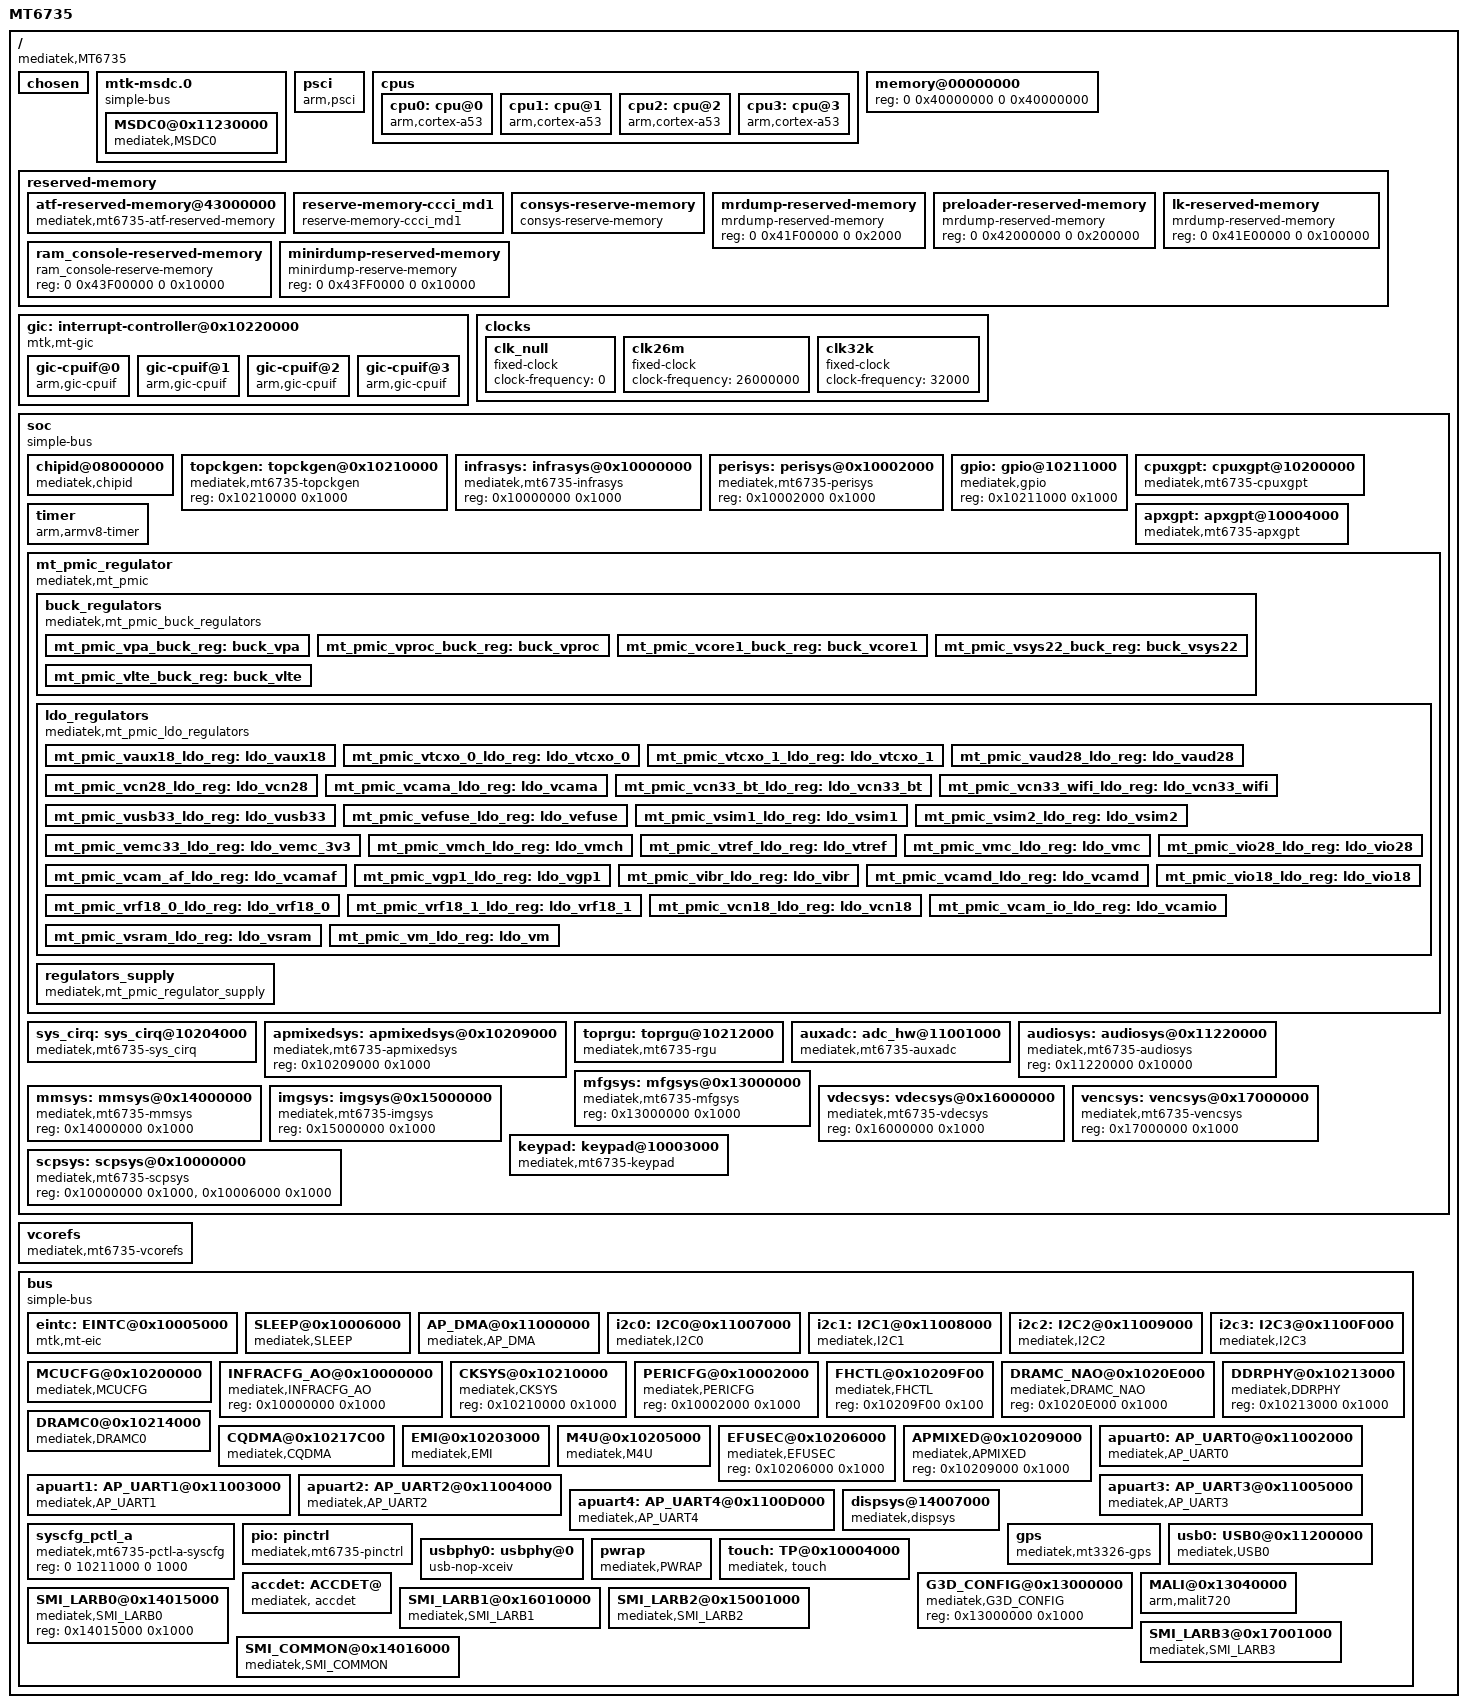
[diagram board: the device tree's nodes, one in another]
/*
 * Mediatek's MT6735 SoC device tree source
 *
 * Copyright (c) 2013 MediaTek Co., Ltd.
 *              http://www.mediatek.com
 *
 */

#include <dt-bindings/clock/mt6735-clk.h>
#include <dt-bindings/interrupt-controller/arm-gic.h>
#include <dt-bindings/interrupt-controller/irq.h>
#include "mt6735-pinfunc.h"

/ {
	model = "MT6735";
	compatible = "mediatek,MT6735";
	interrupt-parent = <&gic>;
	#address-cells = <2>;
	#size-cells = <2>;

	/* chosen */
	chosen {
		bootargs = "console=tty0 console=ttyMT0,921600n1 root=/dev/ram \
initrd=0x44000000,0x300000 loglevel=8 androidboot.hardware=mt6735";
	};

	/* Do not put any bus before mtk-msdc, because it should be mtk-msdc.0 for partition device node usage */
	/*workaround for .0*/
	mtk-msdc.0 {
		compatible = "simple-bus";
		#address-cells = <1>;
		#size-cells = <1>;
		ranges = <0 0 0 0xffffffff>;

		MSDC0@0x11230000 {
			compatible = "mediatek,MSDC0";
			reg = <0x11230000 0x10000  /* MSDC0_BASE   */
			       0x10000E84 0x2>;    /* FPGA PWR_GPIO, PWR_GPIO_EO */
			interrupts = <0 79 0x8>;
		};
	};

	psci {
		compatible  = "arm,psci";
		method      = "smc";
		cpu_suspend = <0x84000001>;
		cpu_off     = <0x84000002>;
		cpu_on      = <0x84000003>;
		affinity_info = <0x84000004>;
	};

	cpus {	#address-cells = <1>;
		#size-cells = <0>;

		cpu0: cpu@0 {
			device_type = "cpu";
			compatible = "arm,cortex-a53";
			reg = <0x000>;
			enable-method = "mt-boot";
			cpu-release-addr = <0x0 0x40000200>;
			clock-frequency = <1300000000>;
		};

		cpu1: cpu@1 {
			device_type = "cpu";
			compatible = "arm,cortex-a53";
			reg = <0x001>;
			enable-method = "mt-boot";
			cpu-release-addr = <0x0 0x40000200>;
			clock-frequency = <1300000000>;
		};

		cpu2: cpu@2 {
			device_type = "cpu";
			compatible = "arm,cortex-a53";
			reg = <0x002>;
			enable-method = "mt-boot";
			cpu-release-addr = <0x0 0x40000200>;
			clock-frequency = <1300000000>;
		};

		cpu3: cpu@3 {
			device_type = "cpu";
			compatible = "arm,cortex-a53";
			reg = <0x003>;
			enable-method = "mt-boot";
			cpu-release-addr = <0x0 0x40000200>;
			clock-frequency = <1300000000>;
		};
/*
		cpu4: cpu@4 {
			device_type = "cpu";
			compatible = "arm,cortex-a53";
			reg = <0x100>;
			enable-method = "mt-boot";
			cpu-release-addr = <0x0 0x40000200>;
			clock-frequency = <2000000000>;
		};

		cpu5: cpu@5 {
			device_type = "cpu";
			compatible = "arm,cortex-a53";
			reg = <0x101>;
			enable-method = "mt-boot";
			cpu-release-addr = <0x0 0x40000200>;
			clock-frequency = <2000000000>;
		};

		cpu6: cpu@6 {
			device_type = "cpu";
			compatible = "arm,cortex-a53";
			reg = <0x102>;
			enable-method = "mt-boot";
			cpu-release-addr = <0x0 0x40000200>;
			clock-frequency = <2000000000>;
		};

		cpu7: cpu@7 {
			device_type = "cpu";
			compatible = "arm,cortex-a53";
			reg = <0x103>;
			enable-method = "mt-boot";
			cpu-release-addr = <0x0 0x40000200>;
			clock-frequency = <2000000000>;

		};
*/
	};

	memory@00000000 {
		device_type = "memory";
		reg = <0 0x40000000 0 0x40000000>;
	};

	reserved-memory {
		#address-cells = <2>;
		#size-cells = <2>;
		ranges;

		/* reserve 192KB at DRAM start + 48MB */
		atf-reserved-memory@43000000 {
			compatible = "mediatek,mt6735-atf-reserved-memory",
				     "mediatek,mt6735m-atf-reserved-memory",
				     "mediatek,mt6753-atf-reserved-memory";
			no-map;
			reg = <0 0x43000000 0 0x30000>;
		};

		reserve-memory-ccci_md1 {
			compatible = "reserve-memory-ccci_md1";
			no-map;
			size = <0 0x3810000>; // md_size+smem_size
			alignment = <0 0x2000000>;
			alloc-ranges = <0 0x40000000 0 0xC0000000>;
		};

		consys-reserve-memory {
			compatible = "consys-reserve-memory";
			no-map;
			size = <0 0x200000>;
			alignment = <0 0x200000>;
		};

		mrdump-reserved-memory {
			compatible = "mrdump-reserved-memory";
			reg = <0 0x41F00000 0 0x2000>;
		};

		preloader-reserved-memory {
			compatible = "mrdump-reserved-memory";
			reg = <0 0x42000000 0 0x200000>;
		};

		lk-reserved-memory {
			compatible = "mrdump-reserved-memory";
			reg = <0 0x41E00000 0 0x100000>;
		};


		/*
		reserve-memory-test {
			compatible = "reserve-memory-test";
			no-map;
			size = <0 0x4000000>;
			alignment = <0 0x2000000>;
		};

		mrdump-reserved-memory {
			compatible = "mrdump";
			reg = <0 0x80000000 0 0x4000000>;
		};
		*/
		ram_console-reserved-memory {
			compatible = "ram_console-reserve-memory";
			reg = <0 0x43F00000 0 0x10000>;
		};

		minirdump-reserved-memory {
			compatible = "minirdump-reserve-memory";
			reg = <0 0x43FF0000 0 0x10000>;
		};
	};

	gic: interrupt-controller@0x10220000 {
		compatible = "mtk,mt-gic";
		#interrupt-cells = <3>;
		#address-cells = <0>;
		interrupt-controller;
		reg = <0 0x10221000 0 0x1000>,
			<0 0x10222000 0 0x1000>,
			<0 0x10200620 0 0x1000>;
		interrupts = <1 9 0xf04>;

		gic-cpuif@0 {
			compatible = "arm,gic-cpuif";
			cpuif-id = <0>;
			cpu = <&cpu0>;
		};

		gic-cpuif@1 {
			compatible = "arm,gic-cpuif";
			cpuif-id = <1>;
			cpu = <&cpu1>;
		};

		gic-cpuif@2 {
			compatible = "arm,gic-cpuif";
			cpuif-id = <2>;
			cpu = <&cpu2>;
		};

		gic-cpuif@3 {
			compatible = "arm,gic-cpuif";
			cpuif-id = <3>;
			cpu = <&cpu3>;
		};


	};

	clocks {
		clk_null: clk_null {
			compatible = "fixed-clock";
			#clock-cells = <0>;
			clock-frequency = <0>;
		};

		clk26m: clk26m {
			compatible = "fixed-clock";
			#clock-cells = <0>;
			clock-frequency = <26000000>;
		};

		clk32k: clk32k {
			compatible = "fixed-clock";
			#clock-cells = <0>;
			clock-frequency = <32000>;
		};
	};

	soc {
		compatible = "simple-bus";
		#address-cells = <1>;
		#size-cells = <1>;
		ranges;

		chipid@08000000 {
			compatible = "mediatek,chipid";
			reg = <0x08000000 0x0004>,
					<0x08000004 0x0004>,
					<0x08000008 0x0004>,
					<0x0800000C 0x0004>;
		};

		topckgen: topckgen@0x10210000 {
			compatible = "mediatek,mt6735-topckgen";
			reg = <0x10210000 0x1000>;
			#clock-cells = <1>;
		};

		infrasys: infrasys@0x10000000 {
			compatible = "mediatek,mt6735-infrasys";
			reg = <0x10000000 0x1000>;
			#clock-cells = <1>;
		};

		perisys: perisys@0x10002000 {
			compatible = "mediatek,mt6735-perisys";
			reg = <0x10002000 0x1000>;
			#clock-cells = <1>;
		};

		gpio: gpio@10211000 {
			compatible = "mediatek,gpio";
			reg = <0x10211000 0x1000>;
		};

		cpuxgpt: cpuxgpt@10200000 {
			compatible = "mediatek,mt6735-cpuxgpt";
			reg = <0x10200000 0x1000>;
			interrupts = <GIC_SPI 64 IRQ_TYPE_LEVEL_HIGH>,
				<GIC_SPI 65 IRQ_TYPE_LEVEL_HIGH>,
				<GIC_SPI 66 IRQ_TYPE_LEVEL_HIGH>,
				<GIC_SPI 67 IRQ_TYPE_LEVEL_HIGH>,
				<GIC_SPI 68 IRQ_TYPE_LEVEL_HIGH>,
				<GIC_SPI 69 IRQ_TYPE_LEVEL_HIGH>,
				<GIC_SPI 70 IRQ_TYPE_LEVEL_HIGH>,
				<GIC_SPI 71 IRQ_TYPE_LEVEL_HIGH>;
		};

		apxgpt: apxgpt@10004000 {
			compatible = "mediatek,mt6735-apxgpt";
			reg = <0x10004000 0x1000>;
			interrupts = <GIC_SPI 152 IRQ_TYPE_LEVEL_LOW>;
			clock-frequency = <13000000>;
		};

		timer {
			compatible = "arm,armv8-timer";
			interrupts = <GIC_PPI 13 IRQ_TYPE_LEVEL_LOW>, /*Secure Physical Timer Event*/
				<GIC_PPI 14 IRQ_TYPE_LEVEL_LOW>, /*Non-Secure Physical Timer Event*/
				<GIC_PPI 11 IRQ_TYPE_LEVEL_LOW>, /*Virtual Timer Event*/
				<GIC_PPI 10 IRQ_TYPE_LEVEL_LOW>; /*Hypervisor Timer Event*/
				clock-frequency = <13000000>;
		};

		mt_pmic_regulator {
			compatible = "mediatek,mt_pmic";
			/*reg = <0x01>*/
			buck_regulators {
			compatible = "mediatek,mt_pmic_buck_regulators";
				mt_pmic_vpa_buck_reg: buck_vpa {
					regulator-name = "vpa";
					regulator-min-microvolt = <500000>;
					regulator-max-microvolt = <3650000>;
					regulator-ramp-delay = <50000>;
					regulator-enable-ramp-delay = <180>;
				};
				mt_pmic_vproc_buck_reg: buck_vproc {
					regulator-name = "vproc";
					regulator-min-microvolt = <600000>;
					regulator-max-microvolt = <1393750>;
					regulator-ramp-delay = <6250>;
					regulator-enable-ramp-delay = <180>;
					regulator-always-on;
					regulator-boot-on;
				};
				mt_pmic_vcore1_buck_reg: buck_vcore1 {
					regulator-name = "vcore1";
					regulator-min-microvolt = <600000>;
					regulator-max-microvolt = <1393750>;
					regulator-ramp-delay = <6250>;
					regulator-enable-ramp-delay = <180>;
					regulator-always-on;
					regulator-boot-on;
				};
				mt_pmic_vsys22_buck_reg: buck_vsys22 {
					regulator-name = "vsys22";
					regulator-min-microvolt = <1200000>;
					regulator-max-microvolt = <1993750>;
					regulator-ramp-delay = <6250>;
					regulator-enable-ramp-delay = <180>;
					regulator-always-on;
					regulator-boot-on;
				};
				mt_pmic_vlte_buck_reg: buck_vlte {
					regulator-name = "vlte";
					regulator-min-microvolt = <600000>;
					regulator-max-microvolt = <1393750>;
					regulator-ramp-delay = <6250>;
					regulator-enable-ramp-delay = <180>;
					regulator-always-on;
					regulator-boot-on;
				};
			};	/* End of buck_regulators */
			ldo_regulators {
				compatible = "mediatek,mt_pmic_ldo_regulators";
				mt_pmic_vaux18_ldo_reg: ldo_vaux18 {
					regulator-name = "vaux18";
					regulator-min-microvolt = <1800000>;
					regulator-max-microvolt = <1800000>;
					regulator-enable-ramp-delay = <264>;
					regulator-boot-on;
				};
				mt_pmic_vtcxo_0_ldo_reg: ldo_vtcxo_0 {
					regulator-name = "vtcxo_0";
					regulator-min-microvolt = <2800000>;
					regulator-max-microvolt = <2800000>;
					regulator-enable-ramp-delay = <110>;
					regulator-boot-on;
				};
				mt_pmic_vtcxo_1_ldo_reg: ldo_vtcxo_1 {
					regulator-name = "vtcxo_1";
					regulator-min-microvolt = <2800000>;
					regulator-max-microvolt = <2800000>;
					regulator-enable-ramp-delay = <110>;
				};
				mt_pmic_vaud28_ldo_reg: ldo_vaud28 {
					regulator-name = "vaud28";
					regulator-min-microvolt = <2800000>;
					regulator-max-microvolt = <2800000>;
					regulator-enable-ramp-delay = <264>;
					regulator-boot-on;
				};
				mt_pmic_vcn28_ldo_reg: ldo_vcn28 {
					regulator-name = "vcn28";
					regulator-min-microvolt = <2800000>;
					regulator-max-microvolt = <2800000>;
					regulator-enable-ramp-delay = <264>;
				};
				mt_pmic_vcama_ldo_reg: ldo_vcama {
					regulator-name = "vcama";
					regulator-min-microvolt = <1500000>;
					regulator-max-microvolt = <2800000>;
					regulator-enable-ramp-delay = <264>;
				};
				mt_pmic_vcn33_bt_ldo_reg: ldo_vcn33_bt {
					regulator-name = "vcn33_bt";
					regulator-min-microvolt = <3300000>;
					regulator-max-microvolt = <3600000>;
					regulator-enable-ramp-delay = <264>;
				};
				mt_pmic_vcn33_wifi_ldo_reg: ldo_vcn33_wifi {
					regulator-name = "vcn33_wifi";
					regulator-min-microvolt = <3300000>;
					regulator-max-microvolt = <3600000>;
					regulator-enable-ramp-delay = <264>;
				};
				mt_pmic_vusb33_ldo_reg: ldo_vusb33 {
					regulator-name = "vusb33";
					regulator-min-microvolt = <3300000>;
					regulator-max-microvolt = <3300000>;
					regulator-enable-ramp-delay = <264>;
					regulator-boot-on;
				};
				mt_pmic_vefuse_ldo_reg: ldo_vefuse {
					regulator-name = "vefuse";
					regulator-min-microvolt = <1800000>;
					regulator-max-microvolt = <2200000>;
					regulator-enable-ramp-delay = <264>;
				};
				mt_pmic_vsim1_ldo_reg: ldo_vsim1 {
					regulator-name = "vsim1";
					regulator-min-microvolt = <1700000>;
					regulator-max-microvolt = <2100000>;
					regulator-enable-ramp-delay = <264>;
				};
				mt_pmic_vsim2_ldo_reg: ldo_vsim2 {
					regulator-name = "vsim2";
					regulator-min-microvolt = <1700000>;
					regulator-max-microvolt = <2100000>;
					regulator-enable-ramp-delay = <264>;
				};
				mt_pmic_vemc33_ldo_reg: ldo_vemc_3v3 {
					regulator-name = "vemc_3v3";
					regulator-min-microvolt = <1800000>;
					regulator-max-microvolt = <3300000>;
					regulator-enable-ramp-delay = <264>;
					regulator-boot-on;
				};
				mt_pmic_vmch_ldo_reg: ldo_vmch {
					regulator-name = "vmch";
					regulator-min-microvolt = <2900000>;
					regulator-max-microvolt = <3300000>;
					regulator-enable-ramp-delay = <44>;
					regulator-boot-on;
				};
				mt_pmic_vtref_ldo_reg: ldo_vtref {
					regulator-name = "vtref";
					regulator-min-microvolt = <1800000>;
					regulator-max-microvolt = <1800000>;
					regulator-enable-ramp-delay = <240>;
				};
				mt_pmic_vmc_ldo_reg: ldo_vmc {
					regulator-name = "vmc";
					regulator-min-microvolt = <1800000>;
					regulator-max-microvolt = <3300000>;
					regulator-enable-ramp-delay = <44>;
					regulator-boot-on;
				};
				mt_pmic_vcam_af_ldo_reg: ldo_vcamaf {
					regulator-name = "vcamaf";
					regulator-min-microvolt = <1200000>;
					regulator-max-microvolt = <3300000>;
					regulator-enable-ramp-delay = <264>;
				};
				mt_pmic_vio28_ldo_reg: ldo_vio28 {
					regulator-name = "vio28";
					regulator-min-microvolt = <2800000>;
					regulator-max-microvolt = <2800000>;
					regulator-enable-ramp-delay = <264>;
					regulator-boot-on;
				};
				mt_pmic_vgp1_ldo_reg: ldo_vgp1 {
					regulator-name = "vgp1";
					regulator-min-microvolt = <1200000>;
					regulator-max-microvolt = <3300000>;
					regulator-enable-ramp-delay = <264>;
				};
				mt_pmic_vibr_ldo_reg: ldo_vibr {
					regulator-name = "vibr";
					regulator-min-microvolt = <1200000>;
					regulator-max-microvolt = <3300000>;
					regulator-enable-ramp-delay = <44>;
				};
				mt_pmic_vcamd_ldo_reg: ldo_vcamd {
					regulator-name = "vcamd";
					regulator-min-microvolt = <900000>;
					regulator-max-microvolt = <1500000>;
					regulator-enable-ramp-delay = <264>;
				};
				mt_pmic_vrf18_0_ldo_reg: ldo_vrf18_0 {
					regulator-name = "vrf18_0";
					regulator-min-microvolt = <1825000>;
					regulator-max-microvolt = <1825000>;
					regulator-enable-ramp-delay = <220>;
				};
				mt_pmic_vrf18_1_ldo_reg: ldo_vrf18_1 {
					regulator-name = "vrf18_1";
					regulator-min-microvolt = <1200000>;
					regulator-max-microvolt = <1825000>;
					regulator-enable-ramp-delay = <220>;
				};
				mt_pmic_vio18_ldo_reg: ldo_vio18 {
					regulator-name = "vio18";
					regulator-min-microvolt = <1800000>;
					regulator-max-microvolt = <1800000>;
					regulator-enable-ramp-delay = <264>;
					regulator-boot-on;
				};
				mt_pmic_vcn18_ldo_reg: ldo_vcn18 {
					regulator-name = "vcn18";
					regulator-min-microvolt = <1800000>;
					regulator-max-microvolt = <1800000>;
					regulator-enable-ramp-delay = <44>;
				};
				mt_pmic_vcam_io_ldo_reg: ldo_vcamio {
					regulator-name = "vcamio";
					regulator-min-microvolt = <1200000>;
					regulator-max-microvolt = <1800000>;
					regulator-enable-ramp-delay = <220>;
				};
				mt_pmic_vsram_ldo_reg: ldo_vsram {
					regulator-name = "vsram";
					regulator-min-microvolt = <700000>;
					regulator-max-microvolt = <1493750>;
					regulator-enable-ramp-delay = <220>;
					regulator-ramp-delay = <6250>;
					regulator-boot-on;
				};
				mt_pmic_vm_ldo_reg: ldo_vm {
					regulator-name = "vm";
					regulator-min-microvolt = <1240000>;
					regulator-max-microvolt = <1540000>;
					regulator-enable-ramp-delay = <264>;
					regulator-boot-on;
				};
			};/* End of ldo_regulators */
			regulators_supply {
				compatible = "mediatek,mt_pmic_regulator_supply";
				VAUX18-supply = <&mt_pmic_vaux18_ldo_reg>;
				VTCXO_0-supply = <&mt_pmic_vtcxo_0_ldo_reg>;
				VTCXO_1-supply = <&mt_pmic_vtcxo_1_ldo_reg>;
				VAUD28-supply = <&mt_pmic_vaud28_ldo_reg>;
				VEFUSE-supply = <&mt_pmic_vefuse_ldo_reg>;
				VSIM1-supply = <&mt_pmic_vsim1_ldo_reg>;
				VSIM2-supply = <&mt_pmic_vsim2_ldo_reg>;
				VEMC_3V3-supply = <&mt_pmic_vemc33_ldo_reg>;
				VMCH-supply = <&mt_pmic_vmch_ldo_reg>;
				VTREF-supply = <&mt_pmic_vtref_ldo_reg>;
				VMC-supply = <&mt_pmic_vmc_ldo_reg>;
				VIO28-supply = <&mt_pmic_vio28_ldo_reg>;
				VIBR-supply = <&mt_pmic_vibr_ldo_reg>;
				VRF18_0-supply = <&mt_pmic_vrf18_0_ldo_reg>;
				VRF18_1-supply = <&mt_pmic_vrf18_1_ldo_reg>;
				VIO18-supply = <&mt_pmic_vio18_ldo_reg>;
				VSRAM-supply = <&mt_pmic_vsram_ldo_reg>;
				VM-supply = <&mt_pmic_vm_ldo_reg>;
			};/* End of regulators_supply */
		};/* End of mt_pmic_regulator */

		sys_cirq: sys_cirq@10204000 {
			compatible = "mediatek,mt6735-sys_cirq";
			reg = <0x10204000 0x1000>;
			interrupts = <GIC_SPI 231 IRQ_TYPE_LEVEL_LOW>;
			mediatek,cirq_num = <159>;
			mediatek,spi_start_offset = <72>;
		};

		apmixedsys: apmixedsys@0x10209000 {
			compatible = "mediatek,mt6735-apmixedsys";
			reg = <0x10209000 0x1000>;
			#clock-cells = <1>;
		};

		toprgu: toprgu@10212000 {
			compatible = "mediatek,mt6735-rgu";
			reg = <0x10212000 0x1000>;
			interrupts = <GIC_SPI 128 IRQ_TYPE_EDGE_FALLING>;
		};

		auxadc: adc_hw@11001000 {
			compatible = "mediatek,mt6735-auxadc";
			reg = <0x11001000 0x1000>;
			interrupts = <GIC_SPI 76 IRQ_TYPE_EDGE_FALLING>;
			clocks = <&perisys PERI_AUXADC>;
			clock-names = "auxadc-main";
		};

		audiosys: audiosys@0x11220000 {
			compatible = "mediatek,mt6735-audiosys";
			reg = <0x11220000 0x10000>;
			#clock-cells = <1>;
		};

		mfgsys: mfgsys@0x13000000 {
			compatible = "mediatek,mt6735-mfgsys";
			reg = <0x13000000 0x1000>;
			#clock-cells = <1>;
		};

		mmsys: mmsys@0x14000000 {
			compatible = "mediatek,mt6735-mmsys";
			reg = <0x14000000 0x1000>;
			#clock-cells = <1>;
		};

		imgsys: imgsys@0x15000000 {
			compatible = "mediatek,mt6735-imgsys";
			reg = <0x15000000 0x1000>;
			#clock-cells = <1>;
		};

		vdecsys: vdecsys@0x16000000 {
			compatible = "mediatek,mt6735-vdecsys";
			reg = <0x16000000 0x1000>;
			#clock-cells = <1>;
		};

		vencsys: vencsys@0x17000000 {
			compatible = "mediatek,mt6735-vencsys";
			reg = <0x17000000 0x1000>;
			#clock-cells = <1>;
		};

		scpsys: scpsys@0x10000000 {
			compatible = "mediatek,mt6735-scpsys";
			reg = <0x10000000 0x1000>, <0x10006000 0x1000>;
			#clock-cells = <1>;
		};

		keypad: keypad@10003000 {
			compatible = "mediatek,mt6735-keypad";
			reg = <0x10003000 0x1000>;
			interrupts = <GIC_SPI 164 IRQ_TYPE_EDGE_FALLING>;
		};
	};

	vcorefs {
		compatible = "mediatek,mt6735-vcorefs";
		clocks = <&topckgen TOP_MUX_AXI>,
			 <&topckgen TOP_SYSPLL_D5>,
			 <&topckgen TOP_SYSPLL1_D4>;
		clock-names = "mux_axi",
			      "syspll_d5",
			      "syspll1_d4";
	};

	bus {
		compatible = "simple-bus";
		#address-cells = <1>;
		#size-cells = <1>;
		ranges = <0 0 0 0xffffffff>;

		eintc: EINTC@0x10005000 {
			compatible = "mtk,mt-eic";
			reg = <0x10005000 0x1000>;
			interrupts = <0 153 0x4>;

			#interrupt-cells = <2>;
			interrupt-controller;

			max_eint_num = <213>;
			mapping_table_entry = <0>;
		};


		SLEEP@0x10006000 {
			compatible = "mediatek,SLEEP";
			reg = <0x10006000 0x1000>;
			interrupts = <0 165 0x8>,
				     <0 166 0x8>,
				     <0 167 0x8>,
				     <0 168 0x8>;
		};

		AP_DMA@0x11000000 {
			compatible = "mediatek,AP_DMA";
			reg = <0x11000000 0x1000>;
			interrupts = <0 114 0x8>;
		};

		i2c0:I2C0@0x11007000 {
			compatible = "mediatek,I2C0";
			cell-index = <0>;
			reg = <0x11007000 0x1000>;
			interrupts = <0 84 0x8>,
						<0 99 0x8>;
			def_speed = <100>;
			clocks = <&perisys PERI_I2C0>, <&perisys PERI_APDMA>;
			clock-names = "i2c0-main", "i2c0-dma";
			clock-frequency = <13600>;
			clock-div = <1>;
		};

		i2c1:I2C1@0x11008000 {
			compatible = "mediatek,I2C1";
			cell-index = <1>;
			reg = <0x11008000 0x1000>;
			interrupts = <0 85 0x8>,
						<0 100 0x8>;
			def_speed = <100>;
			clocks = <&perisys PERI_I2C1>, <&perisys PERI_APDMA>;
			clock-names = "i2c1-main", "i2c1-dma";
			clock-frequency = <13600>;
			clock-div = <1>;
		};

		i2c2:I2C2@0x11009000 {
			compatible = "mediatek,I2C2";
			cell-index = <2>;
			reg = <0x11009000 0x1000>;
			interrupts = <0 86 0x8>,
						<0 101 0x8>;
			def_speed = <100>;
			clocks = <&perisys PERI_I2C2>, <&perisys PERI_APDMA>;
			clock-names = "i2c2-main", "i2c2-dma";
			clock-frequency = <13600>;
			clock-div = <1>;
		};

		i2c3:I2C3@0x1100F000 {
			compatible = "mediatek,I2C3";
			cell-index = <3>;
			reg = <0x1100F000 0x1000>;
			interrupts = <0 87 0x8>,
						<0 102 0x8>;
			def_speed = <100>;
			clocks = <&perisys PERI_I2C3>, <&perisys PERI_APDMA>;
			clock-names = "i2c3-main", "i2c3-dma";
			clock-frequency = <13600>;
			clock-div = <1>;
		};

		MCUCFG@0x10200000 {
			compatible = "mediatek,MCUCFG";
			reg = <0x10200000 0x200>;
			interrupts = <0 71 0x4>;
		};

		INFRACFG_AO@0x10000000 {
			compatible = "mediatek,INFRACFG_AO";
			reg = <0x10000000 0x1000>;
		};

		CKSYS@0x10210000 {
			compatible = "mediatek,CKSYS";
			reg = <0x10210000 0x1000>;
		};

		PERICFG@0x10002000 {
			compatible = "mediatek,PERICFG";
			reg = <0x10002000 0x1000>;
		};

		FHCTL@0x10209F00 {
			compatible = "mediatek,FHCTL";
			reg = <0x10209F00 0x100>;
		};

		DRAMC_NAO@0x1020E000 {
			compatible = "mediatek,DRAMC_NAO";
			reg = <0x1020E000 0x1000>;
		};

		DDRPHY@0x10213000 {
			compatible = "mediatek,DDRPHY";
			reg = <0x10213000 0x1000>;
		};

		DRAMC0@0x10214000 {
			compatible = "mediatek,DRAMC0";
			reg = <0x10214000 0x1000>;
			clocks = <&infrasys INFRA_GCE>;
			clock-names = "infra-cqdma";
		};

		CQDMA@0x10217C00 {
			compatible = "mediatek,CQDMA";
			reg = <0x10217c00 0xC00>;
			interrupts = <0 143 0x8>;
			nr_channel = <1>;
		};

		EMI@0x10203000 {
			compatible = "mediatek,EMI";
			reg = <0x10203000 0x1000>;
			interrupts = <0 136 0x4>;
		};

		M4U@0x10205000 {
			cell-index = <0>;
			compatible = "mediatek,M4U";
			reg = <0x10205000 0x1000>;
			interrupts = <0 146 0x8>;
			clocks = <&infrasys INFRA_M4U>,
				<&mmsys MM_DISP0_SMI_COMMON>,
				<&mmsys MM_DISP0_SMI_LARB0>,
				<&vdecsys VDEC0_VDEC>,
				<&vdecsys VDEC1_LARB>,
				<&imgsys IMG_IMAGE_LARB2_SMI>,
				<&vencsys VENC_VENC>,
				<&vencsys VENC_LARB>;
			clock-names = "infra_m4u",
					"smi_common",
					"m4u_disp0_smi_larb0",
					"m4u_vdec0_vdec",
					"m4u_vdec1_larb",
					"m4u_img_image_larb2_smi",
					"m4u_venc_venc",
					"m4u_venc_larb";
		};

		EFUSEC@0x10206000 {
			compatible = "mediatek,EFUSEC";
			reg = <0x10206000 0x1000>;
		};

		APMIXED@0x10209000 {
			compatible = "mediatek,APMIXED";
			reg = <0x10209000 0x1000>;
		};

		apuart0: AP_UART0@0x11002000 {
			cell-index = <0>;
			compatible = "mediatek,AP_UART0";
			reg = <0x11002000 0x1000>;
			interrupts = <0 91 0x8>;

			clock-frequency = <26000000>;
			clock-div = <1>;
			clock-names = "uart0-main", "uart-apdma";
		};

		apuart1: AP_UART1@0x11003000 {
			cell-index = <1>;
			compatible = "mediatek,AP_UART1";
			reg = <0x11003000 0x1000>;
			interrupts = <0 92 0x8>;

			clock-frequency = <26000000>;
			clock-div = <1>;
			clock-names = "uart1-main";

		};

		apuart2: AP_UART2@0x11004000 {
			cell-index = <2>;
			compatible = "mediatek,AP_UART2";
			reg = <0x11004000 0x1000>;
			interrupts = <0 93 0x8>;

			clock-frequency = <26000000>;
			clock-div = <1>;
			clock-names = "uart2-main";
		};

		apuart3: AP_UART3@0x11005000 {
			cell-index = <3>;
			compatible = "mediatek,AP_UART3";
			reg = <0x11005000 0x1000>;
			interrupts = <0 94 0x8>;

			clock-frequency = <26000000>;
			clock-div = <1>;
			clock-names = "uart3-main";
		};

		apuart4: AP_UART4@0x1100D000 {
			cell-index = <4>;
			compatible = "mediatek,AP_UART4";
			reg = <0x1100D000 0x1000>;
			interrupts = <0 95 0x8>;

			clock-frequency = <26000000>;
			clock-div = <1>;
			clock-names = "uart4-main";
		};

		dispsys@14007000 {
			compatible = "mediatek,dispsys";

			reg = <0x14007000 0x1000>,  /*DISP_OVL0      */
			      <0 0>,		    /*DISP_OVL1      */
			      <0x14008000 0x1000>,  /*DISP_RDMA0     */
			      <0x14009000 0x1000>,  /*DISP_RDMA1     */
			      <0x1400A000 0x1000>,  /*DISP_WDMA0     */
			      <0x1400B000 0x1000>,  /*DISP_COLOR     */
			      <0x1400C000 0x1000>,  /*DISP_CCORR     */
			      <0x1400D000 0x1000>,  /*DISP_AAL       */
			      <0x1400E000 0x1000>,  /*DISP_GAMMA     */
			      <0x1400F000 0x1000>,  /*DISP_DITHER    */
			      <0 0>,		    /*DISP_UFOE      */
			      <0x1100E000 0x1000>,  /*DISP_PWM       */
			      <0 0>,		    /*DISP_WDMA1     */
			      <0x14014000 0x1000>,  /*DISP_MUTEX     */
			      <0x14011000 0x1000>,  /*DISP_DSI0      */
			      <0x14012000 0x1000>,  /*DISP_DPI0      */
			      <0x14000000 0x1000>,  /*DISP_CONFIG    */
			      <0x14015000 0x1000>,  /*DISP_SMI_LARB0 */
			      <0x14016000 0x1000>,  /*DISP_SMI_COMMOM*/
			      <0x14017000 0x1000>,  /*MIPITX0,real chip would use this:<0x14017000 0x1000>;*/
			      <0x10206000 0x1000>,  /*DISP_CONFIG2*/
			      <0x10210000 0x1000>,  /*DISP_CONFIG3*/
			      <0x10211A70 0x000C>,  /*DISP_DPI_IO_DRIVING1 */
			      <0x10211974 0x000C>,  /*DISP_DPI_IO_DRIVING2 */
			      <0x10211B70 0x000C>,  /*DISP_DPI_IO_DRIVING3 */
			      <0x10206044 0x000C>,  /*DISP_DPI_EFUSE */
			      <0x10206514 0x000C>,  /*DISP_DPI_EFUSE_PERMISSION */
			      <0x10206558 0x000C>,  /*DISP_DPI_EFUSE_KEY */
			      <0x102100A0 0x1000>,  /*DISP_TVDPLL_CFG6 */
			      <0x10209270 0x1000>,  /*DISP_TVDPLL_CON0 */
			      <0x10209274 0x1000>,  /*DISP_TVDPLL_CON1 */
			      <0 0>;		    /*DISP_OD      */

			interrupts = <0 193 8>, /*DISP_OVL0 */
				     <0 0 8>,   /*DISP_OVL1 */
				     <0 194 8>, /*DISP_RDMA0 */
				     <0 195 8>, /*DISP_RDMA1 */
				     <0 196 8>, /*DISP_WDMA0 */
				     <0 197 8>, /*DISP_COLOR */
				     <0 198 8>, /*DISP_CCORR */
				     <0 199 8>, /*DISP_AAL */
				     <0 200 8>, /*DISP_GAMMA */
				     <0 201 8>, /*DISP_DITHER */
				     <0 0 8>,   /*DISP_UFOE */
				     <0 117 8>, /*DISP_PWM */
				     <0 0 8>,   /*DISP_WDMA1 */
				     <0 186 8>, /*DISP_MUTEX */
				     <0 203 8>, /*DISP_DSI0 */
				     <0 204 8>, /*DISP_DPI0 */
				     <0 205 8>, /*DISP_CONFIG, 0 means no IRQ*/
				     <0 176 8>, /*DISP_SMI_LARB0 */
				     <0 0 8>,   /*DISP_SMI_COMMOM*/
				     <0 0 8>,   /*MIPITX0,real chip would use this:<0x14017000 0x1000>;*/
				     <0 0 8>,   /*DISP_CONFIG2*/
				     <0 0 8>,   /*DISP_CONFIG3*/
				     <0 0 8>,   /*DISP_DPI_IO_DRIVING */
				     <0 0 8>,   /*DISP_TVDPLL_CFG6 */
				     <0 0 8>,   /*DISP_TVDPLL_CON0 */
				     <0 0 8>,   /*DISP_TVDPLL_CON1 */
				     <0 0 8>;   /*DISP_OD      */

			clocks = <&mmsys MM_DISP0_SMI_COMMON>,
				 <&mmsys MM_DISP0_SMI_LARB0>,
				 <&mmsys MM_DISP0_DISP_OVL0>,
				 <&mmsys MM_DISP0_DISP_RDMA0>,
				 <&mmsys MM_DISP0_DISP_RDMA1>,
				 <&mmsys MM_DISP0_DISP_WDMA0>,
				 <&mmsys MM_DISP0_DISP_COLOR>,
				 <&mmsys MM_DISP0_DISP_CCORR>,
				 <&mmsys MM_DISP0_DISP_AAL>,
				 <&mmsys MM_DISP0_DISP_GAMMA>,
				 <&mmsys MM_DISP0_DISP_DITHER>,
				 <&mmsys MM_DISP1_DSI_ENGINE>,
				 <&mmsys MM_DISP1_DSI_DIGITAL>,
				 <&mmsys MM_DISP1_DPI_ENGINE>,
				 <&mmsys MM_DISP1_DPI_PIXEL>,
				 <&perisys PERI_DISP_PWM>,
				 <&topckgen TOP_MUX_DPI0>,
				 <&topckgen TOP_TVDPLL_CK>,
				 <&topckgen TOP_TVDPLL_D2>,
				 <&topckgen TOP_DPI_CK>,
				 <&scpsys SCP_SYS_DIS>;

			clock-names = "DISP0_SMI_COMMON",
				      "DISP0_SMI_LARB0",
				      "DISP0_DISP_OVL0",
				      "DISP0_DISP_RDMA0",
				      "DISP0_DISP_RDMA1",
				      "DISP0_DISP_WDMA0",
				      "DISP0_DISP_COLOR",
				      "DISP0_DISP_CCORR",
				      "DISP0_DISP_AAL",
				      "DISP0_DISP_GAMMA",
				      "DISP0_DISP_DITHER",
				      "DISP1_DSI_ENGINE",
				      "DISP1_DSI_DIGITAL",
				      "DISP1_DPI_ENGINE",
				      "DISP1_DPI_PIXEL",
				      "DISP_PWM",
				      "MUX_DPI0",
				      "TVDPLL_CK",
				      "TVDPLL_D2",
				      "DPI_CK",
				      "DISP_MTCMOS_CLK";
		};

		syscfg_pctl_a: syscfg_pctl_a {
			compatible = "mediatek,mt6735-pctl-a-syscfg", "syscon";
			reg = <0 10211000 0 1000>;
		};

		pio: pinctrl {
			compatible = "mediatek,mt6735-pinctrl";
			reg = <0 10211000 0 1000>;
			mediatek,pctl-regmap = <&syscfg_pctl_a>;
			pins-are-numbered;
			gpio-controller;
			#gpio-cells = <2>;
			interrupt-controller;
			#interrupt-cells = <2>;

		};

		gps {
			compatible = "mediatek,mt3326-gps";
		};
		usb0:USB0@0x11200000 {
			compatible = "mediatek,USB0";
			cell-index = <0>;
			reg = <0x11200000 0x10000>,
				<0x11210000 0x10000>;
			interrupts = <0 72 0x8>;
			mode = <2>;
			multipoint = <1>;
			dyn_fifo = <1>;
			soft_con = <1>;
			dma = <1>;
			num_eps = <16>;
			dma_channels = <8>;
			clocks = <&perisys PERI_USB0>;
			clock-names = "usb0";
			VUSB33-supply = <&mt_pmic_vusb33_ldo_reg>;
			iddig_gpio = <0 1>;
			drvvbus_gpio = <83 2>;
		};

		usbphy0: usbphy@0 {
			compatible = "usb-nop-xceiv";
		};

		pwrap {
			compatible = "mediatek,PWRAP";
			reg = <0x10001000 0x1000>;
			interrupts = <0 163 0x4>;
		};

		touch: TP@0x10004000 {
			compatible = "mediatek, touch";
			/*VTOUCH-supply = <&mt_pmic_vgp1_ldo_reg>;*/
		};
		accdet: ACCDET@ {
			compatible = "mediatek, accdet";
		};

		G3D_CONFIG@0x13000000 {
			compatible = "mediatek,G3D_CONFIG";
			reg = <0x13000000 0x1000>;
		};

		MALI@0x13040000 {
			compatible = "arm,malit720", "arm,mali-t72x", "arm,malit7xx", "arm,mali-midgard";
			reg = <0x13040000 0x4000>;
			interrupts = <0 212 0x8>, <0 211 0x8>, <0 210 0x8>;
			interrupt-names = "JOB", "MMU", "GPU";
			clock-frequency = <450000000>;
			clocks = <&mfgsys MFG_BG3D>, <&mmsys MM_DISP0_SMI_COMMON>, <&scpsys SCP_SYS_MFG>, <&scpsys SCP_SYS_DIS>;
			clock-names = "mfg-main", "mfg-smi-common", "mtcmos-mfg", "mtcmos-display";
		};

		SMI_LARB0@0x14015000 {
			compatible = "mediatek,SMI_LARB0";
			reg = <0x14015000 0x1000>;
		};

		SMI_LARB1@0x16010000 {
			compatible = "mediatek,SMI_LARB1";
			reg = <0x16010000 0x1000>;
			interrupts = <0 177 0x8>;
		};

		SMI_LARB2@0x15001000 {
			compatible = "mediatek,SMI_LARB2";
			reg = <0x15001000 0x1000>;
			interrupts = <0 178 0x8>;
		};

		SMI_LARB3@0x17001000 {
			compatible = "mediatek,SMI_LARB3";
			reg = <0x17001000 0x1000>;
			interrupts = <0 202 0x8>;
		};

		SMI_COMMON@0x14016000 {
			compatible = "mediatek,SMI_COMMON";
			reg = <0x14016000 0x1000>,  /* SMI_COMMON_EXT */
				<0x14015000 0x1000>,  /* LARB 0 */
				<0x16010000 0x1000>,  /* LARB 1 */
				<0x15001000 0x1000>,  /* LARB 2 */
				<0x17001000 0x1000>;  /* LARB 3 */

		clocks = <&mmsys MM_DISP0_SMI_COMMON>,
			<&mmsys MM_DISP0_SMI_LARB0>,
			<&imgsys IMG_IMAGE_LARB2_SMI>,
			<&vdecsys VDEC0_VDEC>,
			<&vdecsys VDEC1_LARB>,
			<&vencsys VENC_LARB>,
			<&vencsys VENC_VENC>,
			<&scpsys SCP_SYS_VEN>,
			<&scpsys SCP_SYS_VDE>,
			<&scpsys SCP_SYS_ISP>,
			<&scpsys SCP_SYS_DIS>;

			clock-names = "smi-common", "smi-larb0", "img-larb2", "vdec0-vdec", "vdec1-larb", "venc-larb",
			"venc-venc", "mtcmos-ven", "mtcmos-vde", "mtcmos-isp", "mtcmos-dis";
		};
	};

};

/include/ "cust_kpd.dtsi"
/include/ "cust_i2c.dtsi"
/include/ "cust_eint.dtsi"

